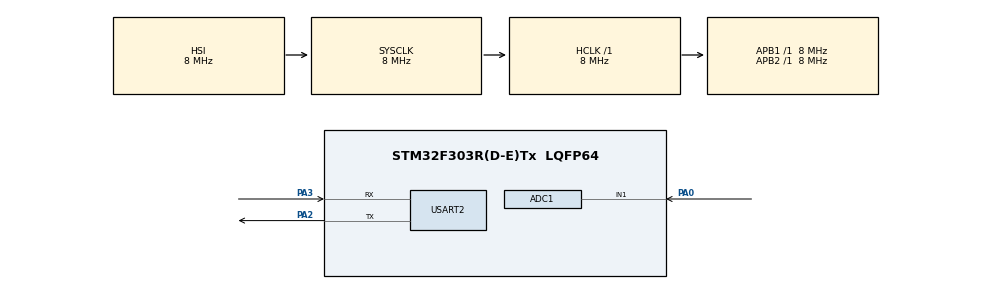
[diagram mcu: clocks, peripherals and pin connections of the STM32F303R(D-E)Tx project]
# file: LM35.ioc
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Mcu.Family=STM32F3
RCC.CortexFreq_Value=8000000
ADC1.SamplingTimeOPAMP-1\#ChannelRegularConversion=ADC_SAMPLETIME_7CYCLES_5
ProjectManager.StackSize=0x400
PA3.Mode=Asynchronous
ProjectManager.TargetToolchain=TrueSTUDIO
ADC1.Offset-1\#ChannelRegularConversion=0
ADC1.Channel-1\#ChannelRegularConversion=ADC_CHANNEL_1
RCC.USBFreq_Value=16000000
RCC.LSE_VALUE=32768
RCC.AHBFreq_Value=8000000
RCC.HSE_VALUE=8000000
board=custom
USART2.VirtualMode-Asynchronous=VM_ASYNC
RCC.APB2Freq_Value=8000000
PA0.Mode=IN1-Single-Ended
Mcu.Name=STM32F303R(D-E)Tx
PA2.Signal=USART2_TX
PA0.Signal=ADC1_IN1
ADC1.SamplingTime-1\#ChannelRegularConversion=ADC_SAMPLETIME_1CYCLE_5
RCC.SYSCLKFreq_VALUE=8000000
Mcu.Package=LQFP64
ADC1.master=1
ADC1.Rank-1\#ChannelRegularConversion=1
ProjectManager.HeapSize=0x200
ADC1.OffsetNumber-1\#ChannelRegularConversion=ADC_OFFSET_NONE
RCC.HSI_VALUE=8000000
NVIC.PriorityGroup=NVIC_PRIORITYGROUP_4
ADC1.NbrOfConversionFlag=1
PA2.Mode=Asynchronous
RCC.APB1Freq_Value=8000000
PA3.Signal=USART2_RX

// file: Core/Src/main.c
/* USER CODE BEGIN Header */
/**
  ******************************************************************************
  * @file           : main.c
  * @brief          : Main program body
  ******************************************************************************
  * @attention
  *
  * <h2><center>&copy; Copyright (c) 2020 STMicroelectronics.
  * All rights reserved.</center></h2>
  *
  * This software component is licensed by ST under BSD 3-Clause license,
  * the "License"; You may not use this file except in compliance with the
  * License. You may obtain a copy of the License at:
  *                        opensource.org/licenses/BSD-3-Clause
  *
  ******************************************************************************
  */
/* USER CODE END Header */
#include "main.h"

ADC_HandleTypeDef hadc1;

UART_HandleTypeDef huart2;

void SystemClock_Config(void);
static void MX_GPIO_Init(void);
static void MX_ADC1_Init(void);
static void MX_USART2_UART_Init(void);

/* USER CODE BEGIN 0 */
uint8_t odczyt;
uint8_t temp = 0;
char send[50];

void readTemp(void){
  	  if (HAL_ADC_PollForConversion(&hadc1, 10) == HAL_OK) {
  		  	  	HAL_ADC_Start(&hadc1);
  	  			odczyt = HAL_ADC_GetValue(&hadc1);
  	  			temp = (odczyt*500)/1023;
    }
  }
/* USER CODE END 0 */

int main(void)
{
  /* USER CODE BEGIN 1 */

  /* USER CODE END WHILE */
  /* USER CODE END 1 */

  /* MCU Configuration--------------------------------------------------------*/

  /* Reset of all peripherals, Initializes the Flash interface and the Systick. */
  HAL_Init();

  /* Configure the system clock */
  SystemClock_Config();

  /* Initialize all configured peripherals */
  MX_GPIO_Init();
  MX_ADC1_Init();
  MX_USART2_UART_Init();

  /* Infinite loop */
  while (1)
  {
	  readTemp();
	  sprintf(send, "Temperatura C  = %.1d\r\n", temp);
	  	  HAL_UART_Transmit(&huart2, (uint8_t *)send, strlen(send), 50);
	  	  HAL_Delay(1000);
  }
}

void SystemClock_Config(void)
{
  RCC_OscInitTypeDef RCC_OscInitStruct = {0};
  RCC_ClkInitTypeDef RCC_ClkInitStruct = {0};
  RCC_PeriphCLKInitTypeDef PeriphClkInit = {0};

  /** Initializes the RCC Oscillators according to the specified parameters
  * in the RCC_OscInitTypeDef structure.
  */
  RCC_OscInitStruct.OscillatorType = RCC_OSCILLATORTYPE_HSI;
  RCC_OscInitStruct.HSIState = RCC_HSI_ON;
  RCC_OscInitStruct.HSICalibrationValue = RCC_HSICALIBRATION_DEFAULT;
  RCC_OscInitStruct.PLL.PLLState = RCC_PLL_ON;
  RCC_OscInitStruct.PLL.PLLSource = RCC_PLLSOURCE_HSI;
  RCC_OscInitStruct.PLL.PLLMUL = RCC_PLL_MUL2;
  RCC_OscInitStruct.PLL.PREDIV = RCC_PREDIV_DIV1;
  if (HAL_RCC_OscConfig(&RCC_OscInitStruct) != HAL_OK)
  {
    Error_Handler();
  }
  /** Initializes the CPU, AHB and APB buses clocks
  */
  RCC_ClkInitStruct.ClockType = RCC_CLOCKTYPE_HCLK|RCC_CLOCKTYPE_SYSCLK
                              |RCC_CLOCKTYPE_PCLK1|RCC_CLOCKTYPE_PCLK2;
  RCC_ClkInitStruct.SYSCLKSource = RCC_SYSCLKSOURCE_HSI;
  RCC_ClkInitStruct.AHBCLKDivider = RCC_SYSCLK_DIV1;
  RCC_ClkInitStruct.APB1CLKDivider = RCC_HCLK_DIV1;
  RCC_ClkInitStruct.APB2CLKDivider = RCC_HCLK_DIV1;

  if (HAL_RCC_ClockConfig(&RCC_ClkInitStruct, FLASH_LATENCY_0) != HAL_OK)
  {
    Error_Handler();
  }
  PeriphClkInit.PeriphClockSelection = RCC_PERIPHCLK_USART2|RCC_PERIPHCLK_ADC12;
  PeriphClkInit.Usart2ClockSelection = RCC_USART2CLKSOURCE_PCLK1;
  PeriphClkInit.Adc12ClockSelection = RCC_ADC12PLLCLK_DIV1;
  if (HAL_RCCEx_PeriphCLKConfig(&PeriphClkInit) != HAL_OK)
  {
    Error_Handler();
  }
}

static void MX_ADC1_Init(void)
{

  ADC_MultiModeTypeDef multimode = {0};
  ADC_ChannelConfTypeDef sConfig = {0};

  /** Common config
  */
  hadc1.Instance = ADC1;
  hadc1.Init.ClockPrescaler = ADC_CLOCK_ASYNC_DIV1;
  hadc1.Init.Resolution = ADC_RESOLUTION_12B;
  hadc1.Init.ScanConvMode = ADC_SCAN_DISABLE;
  hadc1.Init.ContinuousConvMode = DISABLE;
  hadc1.Init.DiscontinuousConvMode = DISABLE;
  hadc1.Init.ExternalTrigConvEdge = ADC_EXTERNALTRIGCONVEDGE_NONE;
  hadc1.Init.ExternalTrigConv = ADC_SOFTWARE_START;
  hadc1.Init.DataAlign = ADC_DATAALIGN_RIGHT;
  hadc1.Init.NbrOfConversion = 1;
  hadc1.Init.DMAContinuousRequests = DISABLE;
  hadc1.Init.EOCSelection = ADC_EOC_SINGLE_CONV;
  hadc1.Init.LowPowerAutoWait = DISABLE;
  hadc1.Init.Overrun = ADC_OVR_DATA_OVERWRITTEN;
  if (HAL_ADC_Init(&hadc1) != HAL_OK)
  {
    Error_Handler();
  }
  /** Configure the ADC multi-mode
  */
  multimode.Mode = ADC_MODE_INDEPENDENT;
  if (HAL_ADCEx_MultiModeConfigChannel(&hadc1, &multimode) != HAL_OK)
  {
    Error_Handler();
  }
  /** Configure Regular Channel
  */
  sConfig.Channel = ADC_CHANNEL_1;
  sConfig.Rank = ADC_REGULAR_RANK_1;
  sConfig.SingleDiff = ADC_SINGLE_ENDED;
  sConfig.SamplingTime = ADC_SAMPLETIME_1CYCLE_5;
  sConfig.OffsetNumber = ADC_OFFSET_NONE;
  sConfig.Offset = 0;
  if (HAL_ADC_ConfigChannel(&hadc1, &sConfig) != HAL_OK)
  {
    Error_Handler();
  }

}

static void MX_USART2_UART_Init(void)
{

  huart2.Instance = USART2;
  huart2.Init.BaudRate = 38400;
  huart2.Init.WordLength = UART_WORDLENGTH_8B;
  huart2.Init.StopBits = UART_STOPBITS_1;
  huart2.Init.Parity = UART_PARITY_NONE;
  huart2.Init.Mode = UART_MODE_TX_RX;
  huart2.Init.HwFlowCtl = UART_HWCONTROL_NONE;
  huart2.Init.OverSampling = UART_OVERSAMPLING_16;
  huart2.Init.OneBitSampling = UART_ONE_BIT_SAMPLE_DISABLE;
  huart2.AdvancedInit.AdvFeatureInit = UART_ADVFEATURE_NO_INIT;
  if (HAL_UART_Init(&huart2) != HAL_OK)
  {
    Error_Handler();
  }

}

static void MX_GPIO_Init(void)
{

  /* GPIO Ports Clock Enable */
  __HAL_RCC_GPIOA_CLK_ENABLE();

}

void Error_Handler(void)
{
}

/************************ (C) COPYRIGHT STMicroelectronics *****END OF FILE****/
